# STM32G07x register map
File version: 1.3
CPU: CM0+ r0p0, little endian, no MPU, no FPU, 3 interrupt priority bits
Registers are 32-bit, read-write, reset 0x0 unless marked. A register's access mark holds for its fields unless they carry their own. Offsets are from the block's base; [hi:lo] are bit positions; {n}, {i} and the like mark numbered series.

## DBG — Debug support
Base 0x40015800
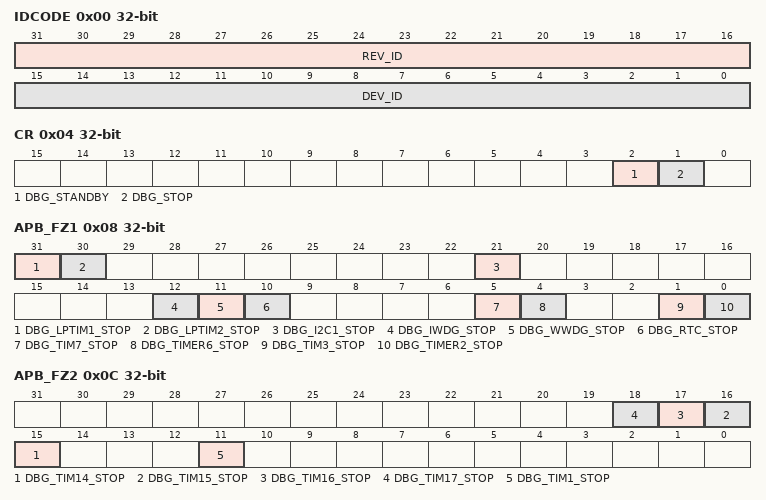
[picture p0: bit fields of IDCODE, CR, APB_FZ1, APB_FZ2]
0x00 IDCODE ro — MCU Device ID Code Register
  [31:16] REV_ID — Revision Identifier
  [15:0] DEV_ID — Device Identifier
0x04 CR — Debug MCU Configuration Register
  [2] DBG_STANDBY — Debug Standby Mode
  [1] DBG_STOP — Debug Stop Mode
0x08 APB_FZ1 — DBG APB freeze register 1
  [31] DBG_LPTIM1_STOP — Clocking of LPTIMER1 counter when the core is halted
  [30] DBG_LPTIM2_STOP — Clocking of LPTIMER2 counter when the core is halted
  [21] DBG_I2C1_STOP — I2C1 SMBUS timeout mode stopped when core is halted
  [12] DBG_IWDG_STOP — Debug Independent Wachdog stopped when Core is halted
  [11] DBG_WWDG_STOP — Debug Window Wachdog stopped when Core is halted
  [10] DBG_RTC_STOP — Debug RTC stopped when Core is halted
  [5] DBG_TIM7_STOP — TIM7 counter stopped when core is halted
  [4] DBG_TIMER6_STOP — Debug Timer 6 stopped when Core is halted
  [1] DBG_TIM3_STOP — TIM3 counter stopped when core is halted
  [0] DBG_TIMER2_STOP — Debug Timer 2 stopped when Core is halted
0x0C APB_FZ2 — DBG APB freeze register 2
  [n+1] DBG_TIM{n}_STOP (n=14..17), [11] DBG_TIM1_STOP

## PWR — Power control
Base 0x40007000
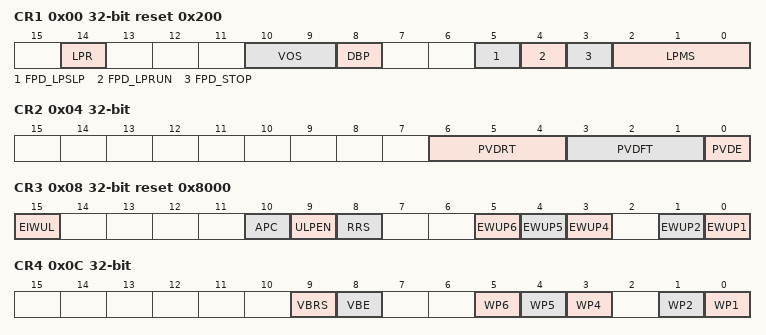
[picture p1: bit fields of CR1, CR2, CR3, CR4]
0x00 CR1 reset 0x200 — Power control register 1
  [14] LPR — Low-power run
  [10:9] VOS — Voltage scaling range selection
  [8] DBP — Disable backup domain write protection
  [5] FPD_LPSLP — Flash memory powered down during Low-power sleep mode
  [4] FPD_LPRUN — Flash memory powered down during Low-power run mode
  [3] FPD_STOP — Flash memory powered down during Stop mode
  [2:0] LPMS — Low-power mode selection
0x04 CR2 — Power control register 2
  [6:4] PVDRT — Power voltage detector rising threshold selection
  [3:1] PVDFT — Power voltage detector falling threshold selection
  [0] PVDE — Power voltage detector enable
0x08 CR3 reset 0x8000 — Power control register 3
  [15] EIWUL — Enable internal wakeup line
  [10] APC — Apply pull-up and pull-down configuration
  [9] ULPEN — Enable the periodical sampling mode for PDR detection
  [8] RRS — SRAM retention in Standby mode
  [5] EWUP6 — Enable WKUP6 wakeup pin
  [4] EWUP5 — Enable WKUP5 wakeup pin
  [3] EWUP4 — Enable Wakeup pin WKUP4
  [1] EWUP2 — Enable Wakeup pin WKUP2
  [0] EWUP1 — Enable Wakeup pin WKUP1
0x0C CR4 — Power control register 4
  [9] VBRS — VBAT battery charging resistor selection
  [8] VBE — VBAT battery charging enable
  [5] WP6 — WKUP6 wakeup pin polarity
  [4] WP5 — Wakeup pin WKUP5 polarity
  [3] WP4 — Wakeup pin WKUP4 polarity
  [1] WP2 — Wakeup pin WKUP2 polarity
  [0] WP1 — Wakeup pin WKUP1 polarity
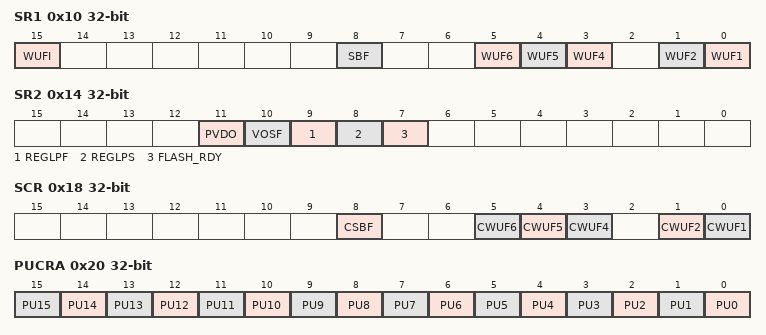
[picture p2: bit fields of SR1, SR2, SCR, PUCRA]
0x10 SR1 ro — Power status register 1
  [15] WUFI — Wakeup flag internal
  [8] SBF — Standby flag
  [5] WUF6 — Wakeup flag 6
  [4] WUF5 — Wakeup flag 5
  [3] WUF4 — Wakeup flag 4
  [1] WUF2 — Wakeup flag 2
  [0] WUF1 — Wakeup flag 1
0x14 SR2 ro — Power status register 2
  [11] PVDO — Power voltage detector output
  [10] VOSF — Voltage scaling flag
  [9] REGLPF — Low-power regulator flag
  [8] REGLPS — Low-power regulator started
  [7] FLASH_RDY — Flash ready flag
0x18 SCR wo — Power status clear register
  [8] CSBF — Clear standby flag
  [5] CWUF6 — Clear wakeup flag 6
  [4] CWUF5 — Clear wakeup flag 5
  [3] CWUF4 — Clear wakeup flag 4
  [1] CWUF2 — Clear wakeup flag 2
  [0] CWUF1 — Clear wakeup flag 1
0x20 PUCRA — Power Port A pull-up control register
  [n] PU{n} (n=0..15) — Port A pull-up bit y (y=0..15)
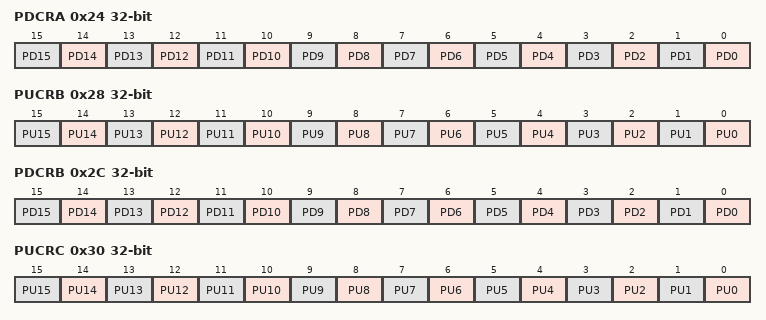
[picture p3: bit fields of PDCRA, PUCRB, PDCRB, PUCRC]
0x24 PDCRA — Power Port A pull-down control register
  [n] PD{n} (n=0..15) — Port A pull-down bit y (y=0..15)
0x28 PUCRB — Power Port B pull-up control register
  [n] PU{n} (n=0..15) — Port B pull-up bit y (y=0..15)
0x2C PDCRB — Power Port B pull-down control register
  [n] PD{n} (n=0..15) — Port B pull-down bit y (y=0..15)
0x30 PUCRC — Power Port C pull-up control register
  [n] PU{n} (n=0..15) — Port C pull-up bit y (y=0..15)
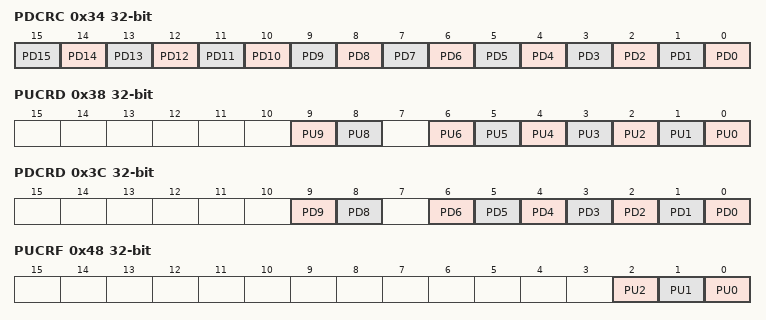
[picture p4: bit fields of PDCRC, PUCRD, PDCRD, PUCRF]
0x34 PDCRC — Power Port C pull-down control register
  [n] PD{n} (n=0..15) — Port C pull-down bit y (y=0..15)
0x38 PUCRD — Power Port D pull-up control register
  [9] PU9 — Port D pull-up bit y (y=0..15)
  [8] PU8 — Port D pull-up bit y (y=0..15)
  [n] PU{n} (n=0..6) — Port D pull-up bit y (y=0..15)
0x3C PDCRD — Power Port D pull-down control register
  [9] PD9 — Port D pull-down bit y (y=0..15)
  [8] PD8 — Port D pull-down bit y (y=0..15)
  [n] PD{n} (n=0..6) — Port D pull-down bit y (y=0..15)
0x48 PUCRF — Power Port F pull-up control register
  [2] PU2 — Port F pull-up bit y (y=0..15)
  [1] PU1 — Port F pull-up bit y (y=0..15)
  [0] PU0 — Port F pull-up bit y (y=0..15)
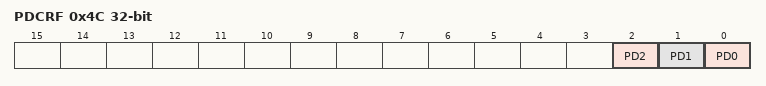
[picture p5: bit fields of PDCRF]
0x4C PDCRF — Power Port F pull-down control register
  [2] PD2 — Port F pull-down bit y (y=0..15)
  [1] PD1 — Port F pull-down bit y (y=0..15)
  [0] PD0 — Port F pull-down bit y (y=0..15)
